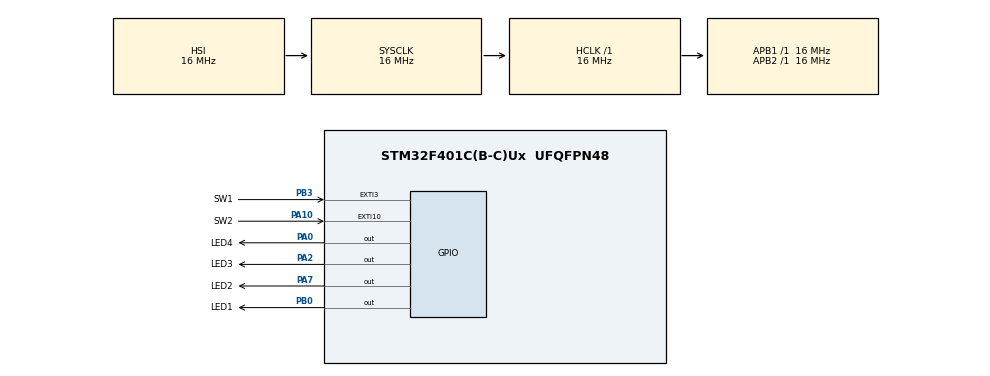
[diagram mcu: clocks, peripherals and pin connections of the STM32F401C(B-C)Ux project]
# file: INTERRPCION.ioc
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Mcu.Family=STM32F4
Mcu.Name=STM32F401C(B-C)Ux
Mcu.Package=UFQFPN48
NVIC.EXTI15_10_IRQn=true\:0\:0\:false\:false\:true\:true\:true\:true
NVIC.EXTI3_IRQn=true\:3\:0\:true\:false\:true\:true\:true\:true
NVIC.PriorityGroup=NVIC_PRIORITYGROUP_4
NVIC.TIM1_UP_TIM10_IRQn=true\:1\:0\:true\:false\:true\:true\:true\:true
PA0-WKUP.GPIO_Label=LED4
PA0-WKUP.Signal=GPIO_Output
PA10.GPIO_Label=SW2
PA10.GPIO_ModeDefaultEXTI=GPIO_MODE_IT_FALLING
PA10.GPIO_PuPd=GPIO_PULLUP
PA10.Signal=GPXTI10
PA2.GPIO_Label=LED3
PA2.Signal=GPIO_Output
PA7.GPIO_Label=LED2
PA7.Signal=GPIO_Output
PB0.GPIO_Label=LED1
PB0.Signal=GPIO_Output
PB3.GPIO_Label=SW1
PB3.GPIO_ModeDefaultEXTI=GPIO_MODE_IT_FALLING
PB3.GPIO_PuPd=GPIO_PULLUP
PB3.Signal=GPXTI3
ProjectManager.HeapSize=0x200
ProjectManager.StackSize=0x400
ProjectManager.TargetToolchain=STM32CubeIDE
RCC.AHBFreq_Value=16000000
RCC.APB1Freq_Value=16000000
RCC.APB2Freq_Value=16000000
RCC.CortexFreq_Value=16000000
RCC.HSE_VALUE=25000000
RCC.HSI_VALUE=16000000
RCC.LSE_VALUE=32768
RCC.SYSCLKFreq_VALUE=16000000
RCC.VCOOutputFreq_Value=192000000
TIM1.AutoReloadPreload=TIM_AUTORELOAD_PRELOAD_ENABLE
TIM1.Period=16000
TIM1.Prescaler=100-1
VP_TIM1_VS_ClockSourceINT.Mode=Internal
board=custom

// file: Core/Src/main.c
/* USER CODE BEGIN Header */
/**
  ******************************************************************************
  * @file           : main.c
  * @brief          : Main program body
  ******************************************************************************
  * @attention
  *
  * Copyright (c) 2024 STMicroelectronics.
  * All rights reserved.
  *
  * This software is licensed under terms that can be found in the LICENSE file
  * in the root directory of this software component.
  * If no LICENSE file comes with this software, it is provided AS-IS.
  *
  ******************************************************************************
  */
/* USER CODE END Header */
#include "main.h"

/* USER CODE BEGIN Includes */
#include "pinout.h"
/* USER CODE END Includes */

TIM_HandleTypeDef htim1;

void SystemClock_Config(void);
static void MX_GPIO_Init(void);
static void MX_TIM1_Init(void);

int main(void)
{

  /* MCU Configuration--------------------------------------------------------*/

  /* Reset of all peripherals, Initializes the Flash interface and the Systick. */
  HAL_Init();

  /* Configure the system clock */
  SystemClock_Config();

  /* Initialize all configured peripherals */
  MX_GPIO_Init();
  MX_TIM1_Init();
  /* USER CODE BEGIN 2 */
  HAL_TIM_Base_Start_IT(&htim1);
  /* USER CODE END 2 */

  /* Infinite loop */
  /* USER CODE BEGIN WHILE */
  while (1)
  {
	PIN_BLINK(LED1);
	HAL_Delay(2000);

    /* USER CODE END WHILE */

  }
}

void SystemClock_Config(void)
{
  RCC_OscInitTypeDef RCC_OscInitStruct = {0};
  RCC_ClkInitTypeDef RCC_ClkInitStruct = {0};

  /** Configure the main internal regulator output voltage
  */
  __HAL_RCC_PWR_CLK_ENABLE();
  __HAL_PWR_VOLTAGESCALING_CONFIG(PWR_REGULATOR_VOLTAGE_SCALE2);

  /** Initializes the RCC Oscillators according to the specified parameters
  * in the RCC_OscInitTypeDef structure.
  */
  RCC_OscInitStruct.OscillatorType = RCC_OSCILLATORTYPE_HSI;
  RCC_OscInitStruct.HSIState = RCC_HSI_ON;
  RCC_OscInitStruct.HSICalibrationValue = RCC_HSICALIBRATION_DEFAULT;
  RCC_OscInitStruct.PLL.PLLState = RCC_PLL_NONE;
  if (HAL_RCC_OscConfig(&RCC_OscInitStruct) != HAL_OK)
  {
    Error_Handler();
  }

  /** Initializes the CPU, AHB and APB buses clocks
  */
  RCC_ClkInitStruct.ClockType = RCC_CLOCKTYPE_HCLK|RCC_CLOCKTYPE_SYSCLK
                              |RCC_CLOCKTYPE_PCLK1|RCC_CLOCKTYPE_PCLK2;
  RCC_ClkInitStruct.SYSCLKSource = RCC_SYSCLKSOURCE_HSI;
  RCC_ClkInitStruct.AHBCLKDivider = RCC_SYSCLK_DIV1;
  RCC_ClkInitStruct.APB1CLKDivider = RCC_HCLK_DIV1;
  RCC_ClkInitStruct.APB2CLKDivider = RCC_HCLK_DIV1;

  if (HAL_RCC_ClockConfig(&RCC_ClkInitStruct, FLASH_LATENCY_0) != HAL_OK)
  {
    Error_Handler();
  }
}

static void MX_TIM1_Init(void)
{

  TIM_ClockConfigTypeDef sClockSourceConfig = {0};
  TIM_MasterConfigTypeDef sMasterConfig = {0};

  htim1.Instance = TIM1;
  htim1.Init.Prescaler = 100-1;
  htim1.Init.CounterMode = TIM_COUNTERMODE_UP;
  htim1.Init.Period = 16000;
  htim1.Init.ClockDivision = TIM_CLOCKDIVISION_DIV1;
  htim1.Init.RepetitionCounter = 0;
  htim1.Init.AutoReloadPreload = TIM_AUTORELOAD_PRELOAD_ENABLE;
  if (HAL_TIM_Base_Init(&htim1) != HAL_OK)
  {
    Error_Handler();
  }
  sClockSourceConfig.ClockSource = TIM_CLOCKSOURCE_INTERNAL;
  if (HAL_TIM_ConfigClockSource(&htim1, &sClockSourceConfig) != HAL_OK)
  {
    Error_Handler();
  }
  sMasterConfig.MasterOutputTrigger = TIM_TRGO_RESET;
  sMasterConfig.MasterSlaveMode = TIM_MASTERSLAVEMODE_DISABLE;
  if (HAL_TIMEx_MasterConfigSynchronization(&htim1, &sMasterConfig) != HAL_OK)
  {
    Error_Handler();
  }

}

static void MX_GPIO_Init(void)
{
  GPIO_InitTypeDef GPIO_InitStruct = {0};

  /* GPIO Ports Clock Enable */
  __HAL_RCC_GPIOA_CLK_ENABLE();
  __HAL_RCC_GPIOB_CLK_ENABLE();

  /*Configure GPIO pin Output Level */
  HAL_GPIO_WritePin(GPIOA, LED4_Pin|LED3_Pin|LED2_Pin, GPIO_PIN_RESET);

  /*Configure GPIO pin Output Level */
  HAL_GPIO_WritePin(LED1_GPIO_Port, LED1_Pin, GPIO_PIN_RESET);

  /*Configure GPIO pins : LED4_Pin LED3_Pin LED2_Pin */
  GPIO_InitStruct.Pin = LED4_Pin|LED3_Pin|LED2_Pin;
  GPIO_InitStruct.Mode = GPIO_MODE_OUTPUT_PP;
  GPIO_InitStruct.Pull = GPIO_NOPULL;
  GPIO_InitStruct.Speed = GPIO_SPEED_FREQ_LOW;
  HAL_GPIO_Init(GPIOA, &GPIO_InitStruct);

  /*Configure GPIO pin : LED1_Pin */
  GPIO_InitStruct.Pin = LED1_Pin;
  GPIO_InitStruct.Mode = GPIO_MODE_OUTPUT_PP;
  GPIO_InitStruct.Pull = GPIO_NOPULL;
  GPIO_InitStruct.Speed = GPIO_SPEED_FREQ_LOW;
  HAL_GPIO_Init(LED1_GPIO_Port, &GPIO_InitStruct);

  /*Configure GPIO pin : SW2_Pin */
  GPIO_InitStruct.Pin = SW2_Pin;
  GPIO_InitStruct.Mode = GPIO_MODE_IT_FALLING;
  GPIO_InitStruct.Pull = GPIO_PULLUP;
  HAL_GPIO_Init(SW2_GPIO_Port, &GPIO_InitStruct);

  /*Configure GPIO pin : SW1_Pin */
  GPIO_InitStruct.Pin = SW1_Pin;
  GPIO_InitStruct.Mode = GPIO_MODE_IT_FALLING;
  GPIO_InitStruct.Pull = GPIO_PULLUP;
  HAL_GPIO_Init(SW1_GPIO_Port, &GPIO_InitStruct);

  /* EXTI interrupt init*/
  HAL_NVIC_SetPriority(EXTI3_IRQn, 3, 0);
  HAL_NVIC_EnableIRQ(EXTI3_IRQn);

  HAL_NVIC_SetPriority(EXTI15_10_IRQn, 0, 0);
  HAL_NVIC_EnableIRQ(EXTI15_10_IRQn);

}

void Error_Handler(void)
{
  __disable_irq();
  while (1)
  {
  }
}
